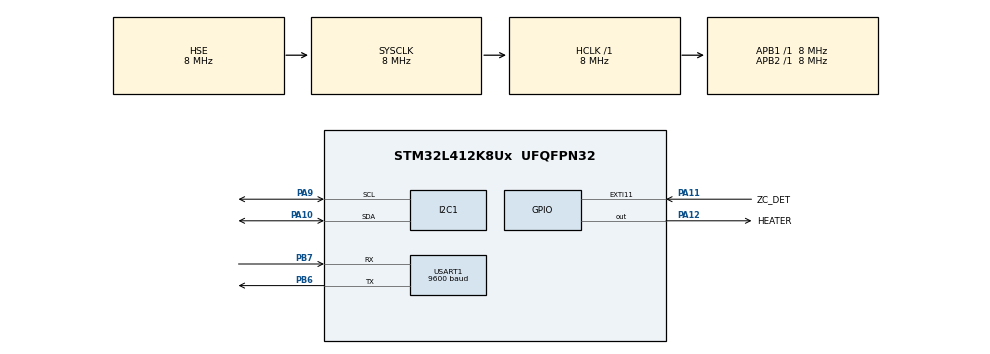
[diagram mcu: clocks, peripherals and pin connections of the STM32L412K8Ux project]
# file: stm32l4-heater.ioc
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I2C1.Timing=0x00201D2B
Mcu.Family=STM32L4
Mcu.Name=STM32L412K8Ux
Mcu.Package=UFQFPN32
NVIC.EXTI15_10_IRQn=true\:0\:0\:false\:false\:true\:true\:true\:true
NVIC.PVD_PVM_IRQn=true\:0\:0\:false\:false\:true\:true\:true\:true
NVIC.PriorityGroup=NVIC_PRIORITYGROUP_4
PA0-CK_IN.Mode=HSE-External-Clock-Source-for-LittleOrca
PA0-CK_IN.Signal=RCC_CK_IN
PA10.Mode=I2C
PA10.Signal=I2C1_SDA
PA11.GPIO_Label=ZC_DET
PA11.GPIO_ModeDefaultEXTI=GPIO_MODE_IT_FALLING
PA11.Signal=GPXTI11
PA12.GPIO_Label=HEATER
PA12.Signal=GPIO_Output
PA13\ (JTMS/SWDIO).Mode=Serial_Wire
PA13\ (JTMS/SWDIO).Signal=SYS_JTMS-SWDIO
PA14\ (JTCK/SWCLK).Mode=Serial_Wire
PA14\ (JTCK/SWCLK).Signal=SYS_JTCK-SWCLK
PA9.Mode=I2C
PA9.Signal=I2C1_SCL
PB6.Mode=Asynchronous
PB6.Signal=USART1_TX
PB7.Mode=Asynchronous
PB7.Signal=USART1_RX
ProjectManager.HeapSize=0x200
ProjectManager.StackSize=0x400
ProjectManager.TargetToolchain=STM32CubeIDE
RCC.ADCFreq_Value=8000000
RCC.AHBFreq_Value=8000000
RCC.APB1Freq_Value=8000000
RCC.APB1TimFreq_Value=8000000
RCC.APB2Freq_Value=8000000
RCC.APB2TimFreq_Value=8000000
RCC.CortexFreq_Value=8000000
RCC.HCLKFreq_Value=8000000
RCC.HSE_VALUE=8000000
RCC.HSI48_VALUE=48000000
RCC.HSI_VALUE=16000000
RCC.LSE_VALUE=32768
RCC.MSI_VALUE=4000000
RCC.PLLSourceVirtual=RCC_PLLSOURCE_HSE
RCC.SYSCLKFreq_VALUE=8000000
RCC.SYSCLKSource=RCC_SYSCLKSOURCE_HSE
RCC.USBFreq_Value=4000000
RCC.VCOOutputFreq_Value=64000000
USART1.BaudRate=9600
USART1.VirtualMode-Asynchronous=VM_ASYNC
VP_LPTIM2_VS_LPTIM_counterModeInternalClock.Mode=Counts__internal_clock_event_00
board=custom

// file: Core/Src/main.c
/* USER CODE BEGIN Header */
/**
  ******************************************************************************
  * @file           : main.c
  * @brief          : Main program body
  ******************************************************************************
  * @attention
  *
  * Copyright (c) 2024 STMicroelectronics.
  * All rights reserved.
  *
  * This software is licensed under terms that can be found in the LICENSE file
  * in the root directory of this software component.
  * If no LICENSE file comes with this software, it is provided AS-IS.
  *
  ******************************************************************************
  */
/* USER CODE END Header */
#include "main.h"
#include "i2c.h"
#include "lptim.h"
#include "usart.h"
#include "gpio.h"

/* USER CODE BEGIN Includes */
#include "my_application.h"
/* USER CODE END Includes */

void SystemClock_Config(void);

int main(void)
{

  /* MCU Configuration--------------------------------------------------------*/

  /* Reset of all peripherals, Initializes the Flash interface and the Systick. */
  HAL_Init();

  /* Configure the system clock */
  SystemClock_Config();

  /* Initialize all configured peripherals */
  MX_GPIO_Init();
  MX_I2C1_Init();
  MX_USART1_UART_Init();
  MX_LPTIM2_Init();
  /* USER CODE BEGIN 2 */
  // ===================================================================
  // This is related to the actual application
  // ===================================================================
  float target_temperature = 25.0f;
  float initialization_time = 0.0f;
  my_application_init(initialization_time, target_temperature);

  /* USER CODE END 2 */

  /* Infinite loop */
  while (1)
  {
	  if(time_to_sleep()){
		  stop_mode();
	  }
  }
}

void SystemClock_Config(void)
{
  RCC_OscInitTypeDef RCC_OscInitStruct = {0};
  RCC_ClkInitTypeDef RCC_ClkInitStruct = {0};

  /** Configure the main internal regulator output voltage
  */
  if (HAL_PWREx_ControlVoltageScaling(PWR_REGULATOR_VOLTAGE_SCALE1) != HAL_OK)
  {
    Error_Handler();
  }

  /** Initializes the RCC Oscillators according to the specified parameters
  * in the RCC_OscInitTypeDef structure.
  */
  RCC_OscInitStruct.OscillatorType = RCC_OSCILLATORTYPE_HSE;
  RCC_OscInitStruct.HSEState = RCC_HSE_BYPASS;
  RCC_OscInitStruct.PLL.PLLState = RCC_PLL_NONE;
  if (HAL_RCC_OscConfig(&RCC_OscInitStruct) != HAL_OK)
  {
    Error_Handler();
  }

  /** Initializes the CPU, AHB and APB buses clocks
  */
  RCC_ClkInitStruct.ClockType = RCC_CLOCKTYPE_HCLK|RCC_CLOCKTYPE_SYSCLK
                              |RCC_CLOCKTYPE_PCLK1|RCC_CLOCKTYPE_PCLK2;
  RCC_ClkInitStruct.SYSCLKSource = RCC_SYSCLKSOURCE_HSE;
  RCC_ClkInitStruct.AHBCLKDivider = RCC_SYSCLK_DIV1;
  RCC_ClkInitStruct.APB1CLKDivider = RCC_HCLK_DIV1;
  RCC_ClkInitStruct.APB2CLKDivider = RCC_HCLK_DIV1;

  if (HAL_RCC_ClockConfig(&RCC_ClkInitStruct, FLASH_LATENCY_0) != HAL_OK)
  {
    Error_Handler();
  }
}

void Error_Handler(void)
{
  __disable_irq();
  while (1)
  {
  }
}
